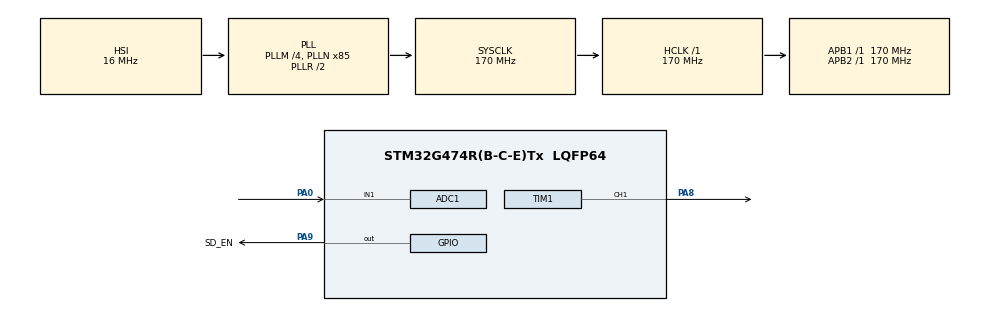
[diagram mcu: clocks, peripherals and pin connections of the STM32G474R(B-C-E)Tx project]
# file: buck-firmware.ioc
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ADC1.Channel-0\#ChannelRegularConversion=ADC_CHANNEL_1
ADC1.NbrOfConversionFlag=1
ADC1.OffsetNumber-0\#ChannelRegularConversion=ADC_OFFSET_NONE
ADC1.Rank-0\#ChannelRegularConversion=1
ADC1.SamplingTime-0\#ChannelRegularConversion=ADC_SAMPLETIME_92CYCLES_5
ADC1.master=1
Mcu.Family=STM32G4
Mcu.Name=STM32G474R(B-C-E)Tx
Mcu.Package=LQFP64
NUCLEO-G474RE.BUTTON=1
NUCLEO-G474RE.LD2=true
NUCLEO-G474RE.VCP=true
NVIC.EXTI15_10_IRQn=true\:0\:0\:false\:false\:true\:false\:true\:true
NVIC.PriorityGroup=NVIC_PRIORITYGROUP_4
PA0.Mode=IN1-Single-Ended
PA0.Signal=ADC1_IN1
PA13.GPIO_Label=T_SWDIO
PA13.Signal=SYS_JTMS-SWDIO
PA14.GPIO_Label=T_SWCLK
PA14.Signal=SYS_JTCK-SWCLK
PA2.Signal=LPUART1_TX
PA3.Signal=LPUART1_RX
PA8.Signal=S_TIM1_CH1
PA9.GPIO_Label=SD_EN
PA9.Signal=GPIO_Output
PB3.GPIO_Label=T_SWO
PB3.Signal=SYS_JTDO-SWO
PC14-OSC32_IN.GPIO_Label=RCC_OSC32_IN
PC14-OSC32_IN.Signal=RCC_OSC32_IN
PC15-OSC32_OUT.GPIO_Label=RCC_OSC32_OUT
PC15-OSC32_OUT.Signal=RCC_OSC32_OUT
PF0-OSC_IN.GPIO_Label=RCC_OSC_IN
PF0-OSC_IN.Signal=RCC_OSC_IN
PF1-OSC_OUT.GPIO_Label=RCC_OSC_OUT
PF1-OSC_OUT.Signal=RCC_OSC_OUT
ProjectManager.HeapSize=0x200
ProjectManager.StackSize=0x400
ProjectManager.TargetToolchain=STM32CubeIDE
RCC.ADC12Freq_Value=170000000
RCC.ADC345Freq_Value=170000000
RCC.AHBFreq_Value=170000000
RCC.APB1Freq_Value=170000000
RCC.APB1TimFreq_Value=170000000
RCC.APB2Freq_Value=170000000
RCC.APB2TimFreq_Value=170000000
RCC.CortexFreq_Value=170000000
RCC.EXTERNAL_CLOCK_VALUE=12288000
RCC.HCLKFreq_Value=170000000
RCC.HSE_VALUE=24000000
RCC.HSI48_VALUE=48000000
RCC.HSI_VALUE=16000000
RCC.LSE_VALUE=32768
RCC.PLLM=RCC_PLLM_DIV4
RCC.PLLN=85
RCC.RTCClockSelection=RCC_RTCCLKSOURCE_LSE
RCC.SYSCLKFreq_VALUE=170000000
RCC.SYSCLKSource=RCC_SYSCLKSOURCE_PLLCLK
RCC.USBFreq_Value=170000000
RCC.VCOOutputFreq_Value=340000000
SH.S_TIM1_CH1.0=TIM1_CH1,PWM Generation1 CH1
TIM1.AutoReloadPreload=TIM_AUTORELOAD_PRELOAD_ENABLE
TIM1.Channel-PWM\ Generation1\ CH1=TIM_CHANNEL_1
TIM1.PeriodNoDither=3399
TIM1.PulseNoDither_1=1417
VP_NUCLEO-G474RE_VS_BSP_COMMON.Mode=COMMON
VP_SYS_VS_DBSignals.Mode=DisableDeadBatterySignals
VP_TIM1_VS_ClockSourceINT.Mode=Internal
board=NUCLEO-G474RE

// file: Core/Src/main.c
/* USER CODE BEGIN Header */
/**
  ******************************************************************************
  * @file           : main.c
  * @brief          : Main program body
  ******************************************************************************
  * @attention
  *
  * Copyright (c) 2026 STMicroelectronics.
  * All rights reserved.
  *
  * This software is licensed under terms that can be found in the LICENSE file
  * in the root directory of this software component.
  * If no LICENSE file comes with this software, it is provided AS-IS.
  *
  ******************************************************************************
  */
/* USER CODE END Header */
#include "main.h"

/* USER CODE BEGIN Includes */
#include <stdio.h>

/* USER CODE END Includes */

/* USER CODE BEGIN PD */
#define VREF_V      3.3f      /* ADC reference voltage */
#define ADC_FULL    4095.0f   /* 12-bit full scale */
#define DIV_RATIO   0.3377f   /* 5.1k / (10k + 5.1k) */
#define V_TARGET    5.0f      /* regulated output, volts */
#define V_TRIP      5.8f      /* above this the output shuts off until RESET */
#define PWM_COUNTS  3400.0f   /* TIM1 counts per period (period register 3399 + 1) */
#define DUTY_MAX    0.55f     /* hard limit on duty cycle */
#define KP          0.002f    /* proportional gain: duty per volt of error */
#define KI          10.0f     /* integral gain: duty per volt-second */
#define TS          0.001f    /* control period in seconds (1 kHz) */

/* USER CODE END PD */

COM_InitTypeDef BspCOMInit;
ADC_HandleTypeDef hadc1;

TIM_HandleTypeDef htim1;

/* USER CODE BEGIN PV */
extern UART_HandleTypeDef hcom_uart[COMn];

/* USER CODE END PV */

void SystemClock_Config(void);
static void MX_GPIO_Init(void);
static void MX_TIM1_Init(void);
static void MX_ADC1_Init(void);

/* USER CODE BEGIN 0 */
/* Average of 16 ADC readings, scaled back up through the divider to real volts */
static float read_vout(void)
{
  uint32_t sum = 0;
  for (int i = 0; i < 16; i++)
  {
    HAL_ADC_Start(&hadc1);
    HAL_ADC_PollForConversion(&hadc1, 1);
    sum += HAL_ADC_GetValue(&hadc1);
  }
  float v_pin = ((float)sum / 16.0f) * VREF_V / ADC_FULL;
  return v_pin / DIV_RATIO;
}

/* Set the PWM duty cycle as a fraction, 0.0 to 1.0 */
static void set_duty(float duty)
{
  __HAL_TIM_SET_COMPARE(&htim1, TIM_CHANNEL_1, (uint32_t)(duty * PWM_COUNTS));
}
/* USER CODE END 0 */

int main(void)
{

  /* MCU Configuration--------------------------------------------------------*/

  /* Reset of all peripherals, Initializes the Flash interface and the Systick. */
  HAL_Init();

  /* Configure the system clock */
  SystemClock_Config();

  /* Initialize all configured peripherals */
  MX_GPIO_Init();
  MX_TIM1_Init();
  MX_ADC1_Init();
  /* USER CODE BEGIN 2 */
  HAL_ADCEx_Calibration_Start(&hadc1, ADC_SINGLE_ENDED);
  set_duty(0.0f);
  HAL_TIM_PWM_Start(&htim1, TIM_CHANNEL_1);

  float vref = 0.0f;        /* target voltage, ramped up slowly (soft start) */
  float integral = 0.0f;    /* running total for the integral term */
  float duty = 0.0f;
  uint8_t tripped = 0;
  uint32_t last_tick = HAL_GetTick();
  uint32_t loop_count = 0;

  /* Enable the gate driver only now. PWM is running at 0 % and the output is at 0 V.
     Through reset and boot, the pull-down on pin 3 keeps the driver off. */
  HAL_GPIO_WritePin(SD_EN_GPIO_Port, SD_EN_Pin, GPIO_PIN_SET);
  /* USER CODE END 2 */

  /* Initialize led */
  BSP_LED_Init(LED_GREEN);

  /* Initialize USER push-button, will be used to trigger an interrupt each time it's pressed.*/
  BSP_PB_Init(BUTTON_USER, BUTTON_MODE_EXTI);

  /* Initialize COM1 port (115200, 8 bits (7-bit data + 1 stop bit), no parity */
  BspCOMInit.BaudRate   = 115200;
  BspCOMInit.WordLength = COM_WORDLENGTH_8B;
  BspCOMInit.StopBits   = COM_STOPBITS_1;
  BspCOMInit.Parity     = COM_PARITY_NONE;
  BspCOMInit.HwFlowCtl  = COM_HWCONTROL_NONE;
  if (BSP_COM_Init(COM1, &BspCOMInit) != BSP_ERROR_NONE)
  {
    Error_Handler();
  }

  /* Infinite loop */
  while (1)
  {

    /* USER CODE BEGIN 3 */
	  if (HAL_GetTick() - last_tick >= 1)          /* runs once per millisecond */
	  {
	    last_tick++;
	    loop_count++;

	    float vout = read_vout();

	    if (vout > V_TRIP)
	    {
	      tripped = 1;                             /* latched until RESET */
	    }

	    if (tripped)
	    {
	      HAL_GPIO_WritePin(SD_EN_GPIO_Port, SD_EN_Pin, GPIO_PIN_RESET);   /* driver off: both MOSFETs off */
	      duty = 0.0f;
	      integral = 0.0f;
	      HAL_GPIO_WritePin(LED2_GPIO_PORT, LED2_PIN, GPIO_PIN_SET);       /* LED solid = tripped */
	    }
	    else
	    {
	      if (vref < V_TARGET) vref += 0.05f;      /* soft start: 0 to 5 V over 100 ms */
	      if (vref > V_TARGET) vref = V_TARGET;

	      float error = vref - vout;
	      integral += KI * TS * error;
	      if (integral < 0.0f)     integral = 0.0f;
	      if (integral > DUTY_MAX) integral = DUTY_MAX;   /* anti-windup */

	      duty = KP * error + integral;
	      if (duty < 0.0f)     duty = 0.0f;
	      if (duty > DUTY_MAX) duty = DUTY_MAX;

	      if (loop_count % 250 == 0) HAL_GPIO_TogglePin(LED2_GPIO_PORT, LED2_PIN);  /* heartbeat */
	    }

	    set_duty(duty);

	    if (loop_count % 5 == 0)                   /* log 200 lines per second */
	    {
	      char msg[40];
	      int n = snprintf(msg, sizeof(msg), "%lu,%d,%d,%d\r\n", (unsigned long)HAL_GetTick(),
	                       (int)(vref * 1000.0f), (int)(vout * 1000.0f), (int)(duty * 1000.0f));
	      HAL_UART_Transmit(&hcom_uart[COM1], (uint8_t *)msg, n, 10);
	    }
	  }
  }
  /* USER CODE END 3 */
}

void SystemClock_Config(void)
{
  RCC_OscInitTypeDef RCC_OscInitStruct = {0};
  RCC_ClkInitTypeDef RCC_ClkInitStruct = {0};

  /** Configure the main internal regulator output voltage
  */
  HAL_PWREx_ControlVoltageScaling(PWR_REGULATOR_VOLTAGE_SCALE1_BOOST);

  /** Initializes the RCC Oscillators according to the specified parameters
  * in the RCC_OscInitTypeDef structure.
  */
  RCC_OscInitStruct.OscillatorType = RCC_OSCILLATORTYPE_HSI;
  RCC_OscInitStruct.HSIState = RCC_HSI_ON;
  RCC_OscInitStruct.HSICalibrationValue = RCC_HSICALIBRATION_DEFAULT;
  RCC_OscInitStruct.PLL.PLLState = RCC_PLL_ON;
  RCC_OscInitStruct.PLL.PLLSource = RCC_PLLSOURCE_HSI;
  RCC_OscInitStruct.PLL.PLLM = RCC_PLLM_DIV4;
  RCC_OscInitStruct.PLL.PLLN = 85;
  RCC_OscInitStruct.PLL.PLLP = RCC_PLLP_DIV2;
  RCC_OscInitStruct.PLL.PLLQ = RCC_PLLQ_DIV2;
  RCC_OscInitStruct.PLL.PLLR = RCC_PLLR_DIV2;
  if (HAL_RCC_OscConfig(&RCC_OscInitStruct) != HAL_OK)
  {
    Error_Handler();
  }

  /** Initializes the CPU, AHB and APB buses clocks
  */
  RCC_ClkInitStruct.ClockType = RCC_CLOCKTYPE_HCLK|RCC_CLOCKTYPE_SYSCLK
                              |RCC_CLOCKTYPE_PCLK1|RCC_CLOCKTYPE_PCLK2;
  RCC_ClkInitStruct.SYSCLKSource = RCC_SYSCLKSOURCE_PLLCLK;
  RCC_ClkInitStruct.AHBCLKDivider = RCC_SYSCLK_DIV1;
  RCC_ClkInitStruct.APB1CLKDivider = RCC_HCLK_DIV1;
  RCC_ClkInitStruct.APB2CLKDivider = RCC_HCLK_DIV1;

  if (HAL_RCC_ClockConfig(&RCC_ClkInitStruct, FLASH_LATENCY_4) != HAL_OK)
  {
    Error_Handler();
  }
}

static void MX_ADC1_Init(void)
{

  ADC_MultiModeTypeDef multimode = {0};
  ADC_ChannelConfTypeDef sConfig = {0};

  /** Common config
  */
  hadc1.Instance = ADC1;
  hadc1.Init.ClockPrescaler = ADC_CLOCK_SYNC_PCLK_DIV4;
  hadc1.Init.Resolution = ADC_RESOLUTION_12B;
  hadc1.Init.DataAlign = ADC_DATAALIGN_RIGHT;
  hadc1.Init.GainCompensation = 0;
  hadc1.Init.ScanConvMode = ADC_SCAN_DISABLE;
  hadc1.Init.EOCSelection = ADC_EOC_SINGLE_CONV;
  hadc1.Init.LowPowerAutoWait = DISABLE;
  hadc1.Init.ContinuousConvMode = DISABLE;
  hadc1.Init.NbrOfConversion = 1;
  hadc1.Init.DiscontinuousConvMode = DISABLE;
  hadc1.Init.ExternalTrigConv = ADC_SOFTWARE_START;
  hadc1.Init.ExternalTrigConvEdge = ADC_EXTERNALTRIGCONVEDGE_NONE;
  hadc1.Init.DMAContinuousRequests = DISABLE;
  hadc1.Init.Overrun = ADC_OVR_DATA_PRESERVED;
  hadc1.Init.OversamplingMode = DISABLE;
  if (HAL_ADC_Init(&hadc1) != HAL_OK)
  {
    Error_Handler();
  }

  /** Configure the ADC multi-mode
  */
  multimode.Mode = ADC_MODE_INDEPENDENT;
  if (HAL_ADCEx_MultiModeConfigChannel(&hadc1, &multimode) != HAL_OK)
  {
    Error_Handler();
  }

  /** Configure Regular Channel
  */
  sConfig.Channel = ADC_CHANNEL_1;
  sConfig.Rank = ADC_REGULAR_RANK_1;
  sConfig.SamplingTime = ADC_SAMPLETIME_92CYCLES_5;
  sConfig.SingleDiff = ADC_SINGLE_ENDED;
  sConfig.OffsetNumber = ADC_OFFSET_NONE;
  sConfig.Offset = 0;
  if (HAL_ADC_ConfigChannel(&hadc1, &sConfig) != HAL_OK)
  {
    Error_Handler();
  }

}

static void MX_TIM1_Init(void)
{

  TIM_ClockConfigTypeDef sClockSourceConfig = {0};
  TIM_MasterConfigTypeDef sMasterConfig = {0};
  TIM_OC_InitTypeDef sConfigOC = {0};
  TIM_BreakDeadTimeConfigTypeDef sBreakDeadTimeConfig = {0};

  htim1.Instance = TIM1;
  htim1.Init.Prescaler = 0;
  htim1.Init.CounterMode = TIM_COUNTERMODE_UP;
  htim1.Init.Period = 3399;
  htim1.Init.ClockDivision = TIM_CLOCKDIVISION_DIV1;
  htim1.Init.RepetitionCounter = 0;
  htim1.Init.AutoReloadPreload = TIM_AUTORELOAD_PRELOAD_ENABLE;
  if (HAL_TIM_Base_Init(&htim1) != HAL_OK)
  {
    Error_Handler();
  }
  sClockSourceConfig.ClockSource = TIM_CLOCKSOURCE_INTERNAL;
  if (HAL_TIM_ConfigClockSource(&htim1, &sClockSourceConfig) != HAL_OK)
  {
    Error_Handler();
  }
  if (HAL_TIM_PWM_Init(&htim1) != HAL_OK)
  {
    Error_Handler();
  }
  sMasterConfig.MasterOutputTrigger = TIM_TRGO_RESET;
  sMasterConfig.MasterOutputTrigger2 = TIM_TRGO2_RESET;
  sMasterConfig.MasterSlaveMode = TIM_MASTERSLAVEMODE_DISABLE;
  if (HAL_TIMEx_MasterConfigSynchronization(&htim1, &sMasterConfig) != HAL_OK)
  {
    Error_Handler();
  }
  sConfigOC.OCMode = TIM_OCMODE_PWM1;
  sConfigOC.Pulse = 1417;
  sConfigOC.OCPolarity = TIM_OCPOLARITY_HIGH;
  sConfigOC.OCNPolarity = TIM_OCNPOLARITY_HIGH;
  sConfigOC.OCFastMode = TIM_OCFAST_DISABLE;
  sConfigOC.OCIdleState = TIM_OCIDLESTATE_RESET;
  sConfigOC.OCNIdleState = TIM_OCNIDLESTATE_RESET;
  if (HAL_TIM_PWM_ConfigChannel(&htim1, &sConfigOC, TIM_CHANNEL_1) != HAL_OK)
  {
    Error_Handler();
  }
  sBreakDeadTimeConfig.OffStateRunMode = TIM_OSSR_DISABLE;
  sBreakDeadTimeConfig.OffStateIDLEMode = TIM_OSSI_DISABLE;
  sBreakDeadTimeConfig.LockLevel = TIM_LOCKLEVEL_OFF;
  sBreakDeadTimeConfig.DeadTime = 0;
  sBreakDeadTimeConfig.BreakState = TIM_BREAK_DISABLE;
  sBreakDeadTimeConfig.BreakPolarity = TIM_BREAKPOLARITY_HIGH;
  sBreakDeadTimeConfig.BreakFilter = 0;
  sBreakDeadTimeConfig.BreakAFMode = TIM_BREAK_AFMODE_INPUT;
  sBreakDeadTimeConfig.Break2State = TIM_BREAK2_DISABLE;
  sBreakDeadTimeConfig.Break2Polarity = TIM_BREAK2POLARITY_HIGH;
  sBreakDeadTimeConfig.Break2Filter = 0;
  sBreakDeadTimeConfig.Break2AFMode = TIM_BREAK_AFMODE_INPUT;
  sBreakDeadTimeConfig.AutomaticOutput = TIM_AUTOMATICOUTPUT_DISABLE;
  if (HAL_TIMEx_ConfigBreakDeadTime(&htim1, &sBreakDeadTimeConfig) != HAL_OK)
  {
    Error_Handler();
  }
  HAL_TIM_MspPostInit(&htim1);

}

static void MX_GPIO_Init(void)
{
  GPIO_InitTypeDef GPIO_InitStruct = {0};

  /* GPIO Ports Clock Enable */
  __HAL_RCC_GPIOC_CLK_ENABLE();
  __HAL_RCC_GPIOF_CLK_ENABLE();
  __HAL_RCC_GPIOA_CLK_ENABLE();
  __HAL_RCC_GPIOB_CLK_ENABLE();

  /*Configure GPIO pin Output Level */
  HAL_GPIO_WritePin(SD_EN_GPIO_Port, SD_EN_Pin, GPIO_PIN_RESET);

  /*Configure GPIO pin : SD_EN_Pin */
  GPIO_InitStruct.Pin = SD_EN_Pin;
  GPIO_InitStruct.Mode = GPIO_MODE_OUTPUT_PP;
  GPIO_InitStruct.Pull = GPIO_NOPULL;
  GPIO_InitStruct.Speed = GPIO_SPEED_FREQ_LOW;
  HAL_GPIO_Init(SD_EN_GPIO_Port, &GPIO_InitStruct);

}

void Error_Handler(void)
{
  __disable_irq();
  while (1)
  {
  }
}
